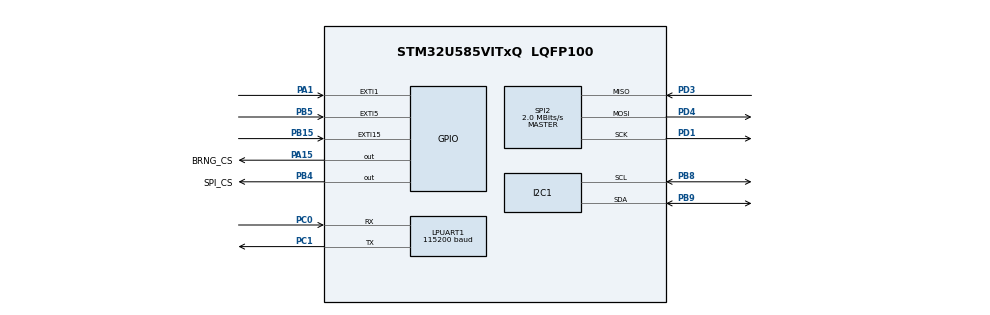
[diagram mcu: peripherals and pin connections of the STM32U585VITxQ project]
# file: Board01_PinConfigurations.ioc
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CORTEX_M33_NS.userName=CORTEX_M33
I2C1.Timing=0x00000E14
LPUART1.BaudRate=115200
Mcu.Family=STM32U5
Mcu.Name=STM32U585VITxQ
Mcu.Package=LQFP100
NVIC.EXTI15_IRQn=true\:0\:0\:false\:true\:true\:3\:true\:true\:true
NVIC.EXTI1_IRQn=true\:0\:0\:false\:true\:true\:1\:true\:true\:true
NVIC.EXTI5_IRQn=true\:0\:0\:false\:true\:true\:2\:true\:true\:true
NVIC.PriorityGroup=NVIC_PRIORITYGROUP_4
NVIC.SPI2_IRQn=true\:0\:0\:false\:true\:true\:4\:true\:true\:true
PA1.Privilege=EXTI_LINE_NPRIV
PA1.Signal=GPXTI1
PA13\ (JTMS/SWDIO).Mode=Serial_Wire
PA13\ (JTMS/SWDIO).Signal=DEBUG_JTMS-SWDIO
PA14\ (JTCK/SWCLK).Mode=Serial_Wire
PA14\ (JTCK/SWCLK).Signal=DEBUG_JTCK-SWCLK
PA15\ (JTDI).GPIO_Label=BRNG_CS
PA15\ (JTDI).Signal=GPIO_Output
PB15.GPIO_ModeDefaultEXTI=GPIO_MODE_IT_FALLING
PB15.Signal=GPXTI15
PB4\ (NJTRST).GPIO_Label=SPI_CS
PB4\ (NJTRST).Signal=GPIO_Output
PB5.GPIO_PuPd=GPIO_PULLDOWN
PB5.Signal=GPXTI5
PB8.Mode=I2C
PB8.Signal=I2C1_SCL
PB9.Mode=I2C
PB9.Signal=I2C1_SDA
PC0.Mode=Asynchronous
PC0.Signal=LPUART1_RX
PC1.Mode=Asynchronous
PC1.Signal=LPUART1_TX
PD1.Mode=Full_Duplex_Master
PD1.Signal=SPI2_SCK
PD3.Mode=Full_Duplex_Master
PD3.Signal=SPI2_MISO
PD4.Mode=Full_Duplex_Master
PD4.Signal=SPI2_MOSI
ProjectManager.HeapSize=0x200
ProjectManager.StackSize=0x400
ProjectManager.TargetToolchain=STM32CubeIDE
RCC.ADCFreq_Value=16000000
RCC.EPOD_VALUE=4000000
RCC.HSE_VALUE=16000000
RCC.HSI48_VALUE=48000000
RCC.HSI_VALUE=16000000
RCC.LSE_VALUE=32768
RCC.LSIDIV_VALUE=32000
RCC.MSI_VALUE=4000000
RCC.USBFreq_Value=48000000
RCC.VCOOutputFreq_Value=516000000
SPI2.CalculateBaudRate=2.0 MBits/s
SPI2.DataSize=SPI_DATASIZE_8BIT
SPI2.Direction=SPI_DIRECTION_2LINES
SPI2.Mode=SPI_MODE_MASTER
SPI2.VirtualType=VM_MASTER
VP_LPBAMQUEUE_VS_QUEUE.Mode=QUEUEMODE
VP_LPBAM_VS_SIG1.Mode=SmartRun
VP_LPBAM_VS_SIG4.Mode=LPDMA1
VP_MEMORYMAP_VS_MEMORYMAP.Mode=CurAppReg
VP_PWR_VS_SECSignals.Mode=Security/Privilege
board=custom

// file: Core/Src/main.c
/* USER CODE BEGIN Header */
/**
  ******************************************************************************
  * @file           : main.c
  * @brief          : Main program body
  ******************************************************************************
  * @attention
  *
  * Copyright (c) 2026 STMicroelectronics.
  * All rights reserved.
  *
  * This software is licensed under terms that can be found in the LICENSE file
  * in the root directory of this software component.
  * If no LICENSE file comes with this software, it is provided AS-IS.
  *
  ******************************************************************************
  */
/* USER CODE END Header */

#include "main.h"
#include "cmsis_os2.h"

// MorseMicro middleware (HaLow)
#include "../../../../HaLow_example_spi/Middlewares/Third_Party/MorseMicro_MM_IoT_MM_IoT/morselib/MM6108/with_wpa_supplicant/include/mmosal.h"

/* USER CODE BEGIN Includes */
#include "../../app/temp_app.h"

/* USER CODE END Includes */

I2C_HandleTypeDef hi2c1;

UART_HandleTypeDef hlpuart1;

SPI_HandleTypeDef hspi2;

void SystemClock_Config(void);
static void MX_GPIO_Init(void);
static void MX_I2C1_Init(void);
static void MX_LPUART1_UART_Init(void);
static void MX_SPI2_Init(void);

void app_init(void);

int main(void)
{

  /* MCU Configuration--------------------------------------------------------*/
  HAL_Init();

  /* Configure the system clock */
  SystemClock_Config();

  /* Initialize all configured peripherals */
  MX_GPIO_Init();
  MX_I2C1_Init();
  MX_LPUART1_UART_Init();
  MX_SPI2_Init();

  /* USER CODE BEGIN 2 */
  // Start MorseMicro/RTOS app flow
  mmosal_main(app_init);
  /* USER CODE END 2 */

  // Should never reach here; RTOS takes over
  while (1) {}
}

// Application entry for MorseMicro/RTOS
void app_init(void)
{
    // Start your application logic here (e.g., create tasks, call temp_app_run_forever, etc.)
    temp_app_run_forever();
}
void SystemClock_Config(void)
{
  RCC_OscInitTypeDef RCC_OscInitStruct = {0};
  RCC_ClkInitTypeDef RCC_ClkInitStruct = {0};

  /** Configure the main internal regulator output voltage
  */
  if (HAL_PWREx_ControlVoltageScaling(PWR_REGULATOR_VOLTAGE_SCALE4) != HAL_OK)
  {
    Error_Handler();
  }

  /** Initializes the CPU, AHB and APB buses clocks
  */
  RCC_OscInitStruct.OscillatorType = RCC_OSCILLATORTYPE_MSI;
  RCC_OscInitStruct.MSIState = RCC_MSI_ON;
  RCC_OscInitStruct.MSICalibrationValue = RCC_MSICALIBRATION_DEFAULT;
  RCC_OscInitStruct.MSIClockRange = RCC_MSIRANGE_4;
  RCC_OscInitStruct.PLL.PLLState = RCC_PLL_NONE;
  if (HAL_RCC_OscConfig(&RCC_OscInitStruct) != HAL_OK)
  {
    Error_Handler();
  }

  /** Initializes the CPU, AHB and APB buses clocks
  */
  RCC_ClkInitStruct.ClockType = RCC_CLOCKTYPE_HCLK|RCC_CLOCKTYPE_SYSCLK
                              |RCC_CLOCKTYPE_PCLK1|RCC_CLOCKTYPE_PCLK2
                              |RCC_CLOCKTYPE_PCLK3;
  RCC_ClkInitStruct.SYSCLKSource = RCC_SYSCLKSOURCE_MSI;
  RCC_ClkInitStruct.AHBCLKDivider = RCC_SYSCLK_DIV1;
  RCC_ClkInitStruct.APB1CLKDivider = RCC_HCLK_DIV1;
  RCC_ClkInitStruct.APB2CLKDivider = RCC_HCLK_DIV1;
  RCC_ClkInitStruct.APB3CLKDivider = RCC_HCLK_DIV1;

  if (HAL_RCC_ClockConfig(&RCC_ClkInitStruct, FLASH_LATENCY_0) != HAL_OK)
  {
    Error_Handler();
  }
}

static void MX_I2C1_Init(void)
{

  hi2c1.Instance = I2C1;
  hi2c1.Init.Timing = 0x00000E14;
  hi2c1.Init.OwnAddress1 = 0;
  hi2c1.Init.AddressingMode = I2C_ADDRESSINGMODE_7BIT;
  hi2c1.Init.DualAddressMode = I2C_DUALADDRESS_DISABLE;
  hi2c1.Init.OwnAddress2 = 0;
  hi2c1.Init.OwnAddress2Masks = I2C_OA2_NOMASK;
  hi2c1.Init.GeneralCallMode = I2C_GENERALCALL_DISABLE;
  hi2c1.Init.NoStretchMode = I2C_NOSTRETCH_DISABLE;
  if (HAL_I2C_Init(&hi2c1) != HAL_OK)
  {
    Error_Handler();
  }

  /** Configure Analogue filter
  */
  if (HAL_I2CEx_ConfigAnalogFilter(&hi2c1, I2C_ANALOGFILTER_ENABLE) != HAL_OK)
  {
    Error_Handler();
  }

  /** Configure Digital filter
  */
  if (HAL_I2CEx_ConfigDigitalFilter(&hi2c1, 0) != HAL_OK)
  {
    Error_Handler();
  }

}

static void MX_LPUART1_UART_Init(void)
{

  hlpuart1.Instance = LPUART1;
  hlpuart1.Init.BaudRate = 115200;
  hlpuart1.Init.WordLength = UART_WORDLENGTH_8B;
  hlpuart1.Init.StopBits = UART_STOPBITS_1;
  hlpuart1.Init.Parity = UART_PARITY_NONE;
  hlpuart1.Init.Mode = UART_MODE_TX_RX;
  hlpuart1.Init.HwFlowCtl = UART_HWCONTROL_NONE;
  hlpuart1.Init.OneBitSampling = UART_ONE_BIT_SAMPLE_DISABLE;
  hlpuart1.Init.ClockPrescaler = UART_PRESCALER_DIV1;
  hlpuart1.AdvancedInit.AdvFeatureInit = UART_ADVFEATURE_NO_INIT;
  hlpuart1.FifoMode = UART_FIFOMODE_DISABLE;
  if (HAL_UART_Init(&hlpuart1) != HAL_OK)
  {
    Error_Handler();
  }
  if (HAL_UARTEx_SetTxFifoThreshold(&hlpuart1, UART_TXFIFO_THRESHOLD_1_8) != HAL_OK)
  {
    Error_Handler();
  }
  if (HAL_UARTEx_SetRxFifoThreshold(&hlpuart1, UART_RXFIFO_THRESHOLD_1_8) != HAL_OK)
  {
    Error_Handler();
  }
  if (HAL_UARTEx_DisableFifoMode(&hlpuart1) != HAL_OK)
  {
    Error_Handler();
  }

}

static void MX_SPI2_Init(void)
{

  SPI_AutonomousModeConfTypeDef HAL_SPI_AutonomousMode_Cfg_Struct = {0};

  /* SPI2 parameter configuration*/
  hspi2.Instance = SPI2;
  hspi2.Init.Mode = SPI_MODE_MASTER;
  hspi2.Init.Direction = SPI_DIRECTION_2LINES;
  hspi2.Init.DataSize = SPI_DATASIZE_8BIT;
  hspi2.Init.CLKPolarity = SPI_POLARITY_LOW;
  hspi2.Init.CLKPhase = SPI_PHASE_1EDGE;
  hspi2.Init.NSS = SPI_NSS_SOFT;
  hspi2.Init.BaudRatePrescaler = SPI_BAUDRATEPRESCALER_2;
  hspi2.Init.FirstBit = SPI_FIRSTBIT_MSB;
  hspi2.Init.TIMode = SPI_TIMODE_DISABLE;
  hspi2.Init.CRCCalculation = SPI_CRCCALCULATION_DISABLE;
  hspi2.Init.CRCPolynomial = 0x7;
  hspi2.Init.NSSPMode = SPI_NSS_PULSE_ENABLE;
  hspi2.Init.NSSPolarity = SPI_NSS_POLARITY_LOW;
  hspi2.Init.FifoThreshold = SPI_FIFO_THRESHOLD_01DATA;
  hspi2.Init.MasterSSIdleness = SPI_MASTER_SS_IDLENESS_00CYCLE;
  hspi2.Init.MasterInterDataIdleness = SPI_MASTER_INTERDATA_IDLENESS_00CYCLE;
  hspi2.Init.MasterReceiverAutoSusp = SPI_MASTER_RX_AUTOSUSP_DISABLE;
  hspi2.Init.MasterKeepIOState = SPI_MASTER_KEEP_IO_STATE_DISABLE;
  hspi2.Init.IOSwap = SPI_IO_SWAP_DISABLE;
  hspi2.Init.ReadyMasterManagement = SPI_RDY_MASTER_MANAGEMENT_INTERNALLY;
  hspi2.Init.ReadyPolarity = SPI_RDY_POLARITY_HIGH;
  if (HAL_SPI_Init(&hspi2) != HAL_OK)
  {
    Error_Handler();
  }
  HAL_SPI_AutonomousMode_Cfg_Struct.TriggerState = SPI_AUTO_MODE_DISABLE;
  HAL_SPI_AutonomousMode_Cfg_Struct.TriggerSelection = SPI_GRP1_GPDMA_CH0_TCF_TRG;
  HAL_SPI_AutonomousMode_Cfg_Struct.TriggerPolarity = SPI_TRIG_POLARITY_RISING;
  if (HAL_SPIEx_SetConfigAutonomousMode(&hspi2, &HAL_SPI_AutonomousMode_Cfg_Struct) != HAL_OK)
  {
    Error_Handler();
  }

}

static void MX_GPIO_Init(void)
{
  GPIO_InitTypeDef GPIO_InitStruct = {0};

  /* GPIO Ports Clock Enable */
  __HAL_RCC_GPIOC_CLK_ENABLE();
  __HAL_RCC_GPIOA_CLK_ENABLE();
  __HAL_RCC_GPIOB_CLK_ENABLE();
  __HAL_RCC_GPIOD_CLK_ENABLE();

  /*Configure GPIO pin Output Level */
  HAL_GPIO_WritePin(GPIOA, GPIO_PIN_15, GPIO_PIN_RESET);

  /*Configure GPIO pin Output Level */
  HAL_GPIO_WritePin(GPIOB, GPIO_PIN_4, GPIO_PIN_RESET);

  /*Configure GPIO pin : PA1 */
  GPIO_InitStruct.Pin = GPIO_PIN_1;
  GPIO_InitStruct.Mode = GPIO_MODE_IT_RISING;
  GPIO_InitStruct.Pull = GPIO_NOPULL;
  HAL_GPIO_Init(GPIOA, &GPIO_InitStruct);

  /*Configure GPIO pin : PB15 */
  GPIO_InitStruct.Pin = GPIO_PIN_15;
  GPIO_InitStruct.Mode = GPIO_MODE_IT_FALLING;
  GPIO_InitStruct.Pull = GPIO_NOPULL;
  HAL_GPIO_Init(GPIOB, &GPIO_InitStruct);

  /*Configure GPIO pin : PA15 */
  GPIO_InitStruct.Pin = GPIO_PIN_15;
  GPIO_InitStruct.Mode = GPIO_MODE_OUTPUT_PP;
  GPIO_InitStruct.Pull = GPIO_NOPULL;
  GPIO_InitStruct.Speed = GPIO_SPEED_FREQ_LOW;
  HAL_GPIO_Init(GPIOA, &GPIO_InitStruct);

  /*Configure GPIO pin : PB4 */
  GPIO_InitStruct.Pin = GPIO_PIN_4;
  GPIO_InitStruct.Mode = GPIO_MODE_OUTPUT_PP;
  GPIO_InitStruct.Pull = GPIO_NOPULL;
  GPIO_InitStruct.Speed = GPIO_SPEED_FREQ_LOW;
  HAL_GPIO_Init(GPIOB, &GPIO_InitStruct);

  /*Configure GPIO pin : PB5 */
  GPIO_InitStruct.Pin = GPIO_PIN_5;
  GPIO_InitStruct.Mode = GPIO_MODE_IT_RISING;
  GPIO_InitStruct.Pull = GPIO_PULLDOWN;
  HAL_GPIO_Init(GPIOB, &GPIO_InitStruct);

}

void Error_Handler(void)
{
  __disable_irq();
  while (1)
  {
  }
}
